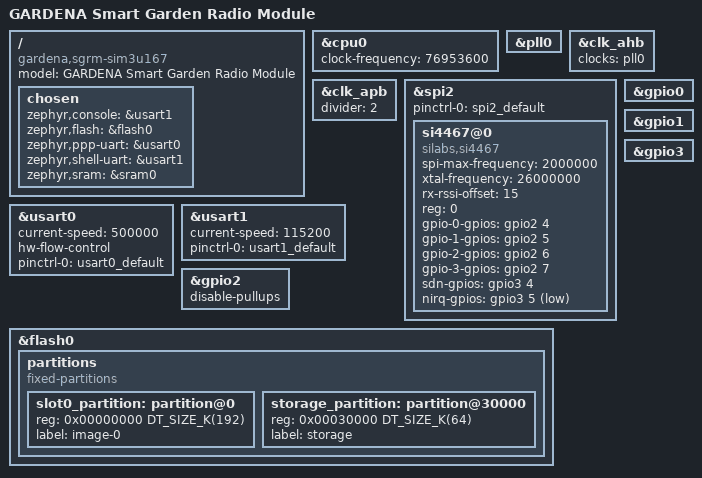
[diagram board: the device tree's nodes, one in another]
/*
 * Copyright (c) 2024 GARDENA GmbH
 *
 * SPDX-License-Identifier: Apache-2.0
 */

/dts-v1/;
#include <silabs/sim3u167.dtsi>
#include "sgrm-pinctrl.dtsi"

/ {
	model = "GARDENA Smart Garden Radio Module";
	compatible = "gardena,sgrm-sim3u167", "silabs,sim3u167", "silabs,sim3u";

	chosen {
		zephyr,console = &usart1;
		zephyr,flash = &flash0;
		zephyr,ppp-uart = &usart0;
		zephyr,shell-uart = &usart1;
		zephyr,sram = &sram0;
	};
};

&cpu0 {
	clock-frequency = <76953600>;
};

&pll0 {
	status = "okay";
};

&clk_ahb {
	clocks = <&pll0>;
	status = "okay";
};

&clk_apb {
	divider = <2>;
	status = "okay";
};

&spi2 {
	pinctrl-0 = <&spi2_default>;
	pinctrl-names = "default";
	status = "okay";

	si4467@0 {
		compatible = "silabs,si4467";
		spi-max-frequency = <2000000>;
		xtal-frequency = <26000000>;
		rx-rssi-offset = <15>;
		reg = <0>;
		gpio-0-gpios = <&gpio2 4 GPIO_ACTIVE_HIGH>;
		gpio-1-gpios = <&gpio2 5 GPIO_ACTIVE_HIGH>;
		gpio-2-gpios = <&gpio2 6 GPIO_ACTIVE_HIGH>;
		gpio-3-gpios = <&gpio2 7 GPIO_ACTIVE_HIGH>;

		sdn-gpios    = <&gpio3 4 GPIO_ACTIVE_HIGH>;
		nirq-gpios   = <&gpio3 5 GPIO_ACTIVE_LOW>;
	};
};

&usart0 {
	current-speed = <500000>;
	hw-flow-control;
	pinctrl-0 = <&usart0_default>;
	pinctrl-names = "default";
	status = "okay";
};

&usart1 {
	current-speed = <115200>;
	pinctrl-0 = <&usart1_default>;
	pinctrl-names = "default";
	status = "okay";
};

&gpio0 {
	status = "okay";
};

&gpio1 {
	status = "okay";
};

&gpio2 {
	disable-pullups;
	status = "okay";
};

&gpio3 {
	status = "okay";
};

&flash0 {
	status = "okay";

	partitions {
		compatible = "fixed-partitions";
		#address-cells = <1>;
		#size-cells = <1>;

		slot0_partition: partition@0 {
			reg = <0x00000000 DT_SIZE_K(192)>;
			label = "image-0";
		};

		storage_partition: partition@30000 {
			reg = <0x00030000 DT_SIZE_K(64)>;
			label = "storage";
		};
	};
};
